AUTOSAR XML (schema 00046)
package /ComponentTypes
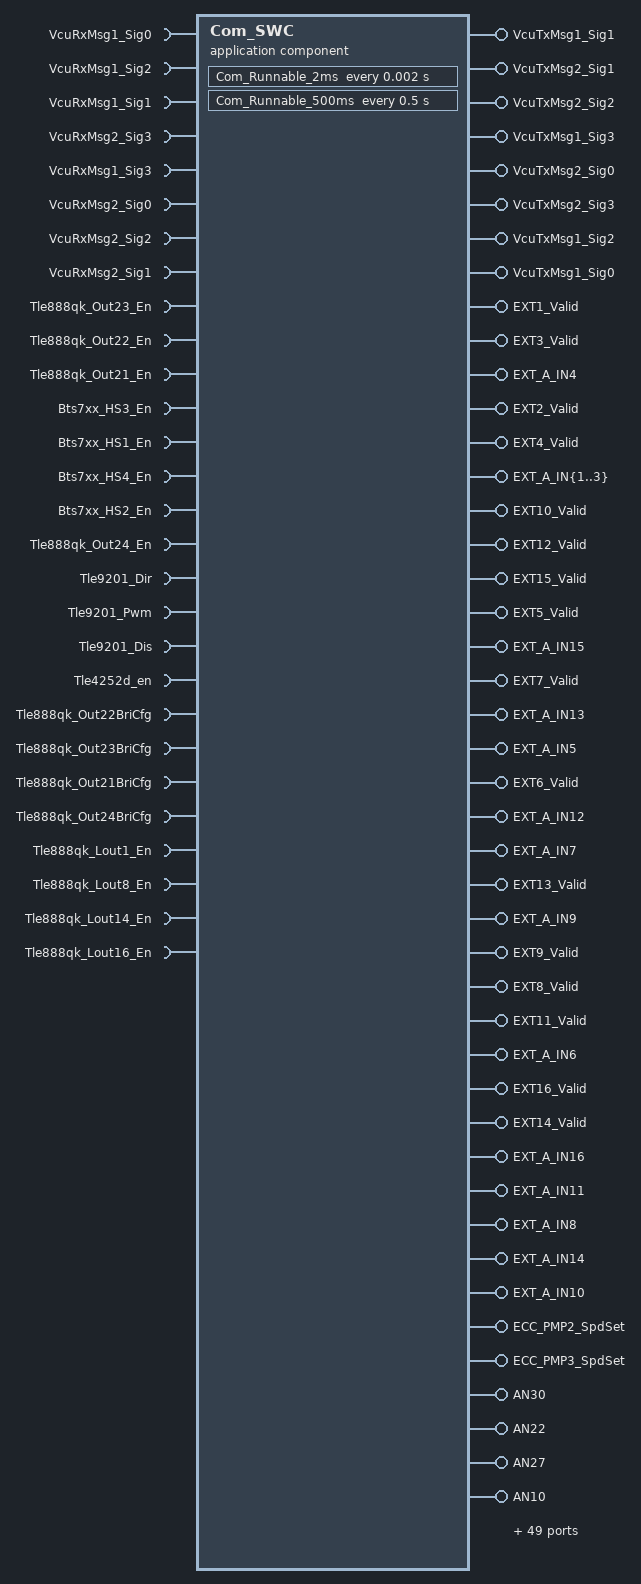
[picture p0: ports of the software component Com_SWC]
  application sw component type Com_SWC
    8 x require port:
      VcuRxMsg1_Sig0: nonqueued-receiver-com-spec{data-element=VcuRxMsg1_Sig0, alive-timeout=2, init-value=0}, required-interface=VcuRxMsg1_Sig0
      VcuRxMsg1_Sig2: nonqueued-receiver-com-spec{data-element=VcuRxMsg1_Sig2, alive-timeout=2, init-value=0}, required-interface=VcuRxMsg1_Sig2
      VcuRxMsg1_Sig1: nonqueued-receiver-com-spec{data-element=VcuRxMsg1_Sig1, alive-timeout=2, init-value=0}, required-interface=VcuRxMsg1_Sig1
      VcuRxMsg2_Sig3: nonqueued-receiver-com-spec{data-element=VcuRxMsg2_Sig3, alive-timeout=2, init-value=0}, required-interface=VcuRxMsg2_Sig3
      VcuRxMsg1_Sig3: nonqueued-receiver-com-spec{data-element=VcuRxMsg1_Sig3, alive-timeout=2, init-value=0}, required-interface=VcuRxMsg1_Sig3
      VcuRxMsg2_Sig0: nonqueued-receiver-com-spec{data-element=VcuRxMsg2_Sig0, alive-timeout=2, init-value=0}, required-interface=VcuRxMsg2_Sig0
      VcuRxMsg2_Sig2: nonqueued-receiver-com-spec{data-element=VcuRxMsg2_Sig2, alive-timeout=2, init-value=0}, required-interface=VcuRxMsg2_Sig2
      VcuRxMsg2_Sig1: nonqueued-receiver-com-spec{data-element=VcuRxMsg2_Sig1, alive-timeout=2, init-value=0}, required-interface=VcuRxMsg2_Sig1
    90 x provide port:
      VcuTxMsg1_Sig1: nonqueued-sender-com-spec{data-element=VcuTxMsg1_Sig1, init-value=0}, provided-interface=VcuTxMsg1_Sig1
      VcuTxMsg2_Sig1: nonqueued-sender-com-spec{data-element=VcuTxMsg2_Sig1, init-value=0}, provided-interface=VcuTxMsg2_Sig1
      VcuTxMsg2_Sig2: nonqueued-sender-com-spec{data-element=VcuTxMsg2_Sig2, init-value=0}, provided-interface=VcuTxMsg2_Sig2
      VcuTxMsg1_Sig3: nonqueued-sender-com-spec{data-element=VcuTxMsg1_Sig3, init-value=0}, provided-interface=VcuTxMsg1_Sig3
      VcuTxMsg2_Sig0: nonqueued-sender-com-spec{data-element=VcuTxMsg2_Sig0, init-value=0}, provided-interface=VcuTxMsg2_Sig0
      VcuTxMsg2_Sig3: nonqueued-sender-com-spec{data-element=VcuTxMsg2_Sig3, init-value=0}, provided-interface=VcuTxMsg2_Sig3
      VcuTxMsg1_Sig2: nonqueued-sender-com-spec{data-element=VcuTxMsg1_Sig2, init-value=0}, provided-interface=VcuTxMsg1_Sig2
      VcuTxMsg1_Sig0: nonqueued-sender-com-spec{data-element=VcuTxMsg1_Sig0, init-value=0}, provided-interface=VcuTxMsg1_Sig0
      EXT1_Valid: nonqueued-sender-com-spec{data-element=EXT1_Valid, init-value=0}, provided-interface=EXT1_Valid
      EXT3_Valid: nonqueued-sender-com-spec{data-element=EXT3_Valid, init-value=0}, provided-interface=EXT3_Valid
      EXT_A_IN4: nonqueued-sender-com-spec{data-element=EXT_A_IN4, init-value=0}, provided-interface=EXT_A_IN4
      EXT2_Valid: nonqueued-sender-com-spec{data-element=EXT2_Valid, init-value=0}, provided-interface=EXT2_Valid
      EXT4_Valid: nonqueued-sender-com-spec{data-element=EXT4_Valid, init-value=0}, provided-interface=EXT4_Valid
      EXT_A_IN{1..3}: nonqueued-sender-com-spec{data-element=EXT_A_IN{1..3}, init-value=0}, provided-interface=EXT_A_IN{1..3}
      EXT10_Valid: nonqueued-sender-com-spec{data-element=EXT10_Valid, init-value=0}, provided-interface=EXT10_Valid
      EXT12_Valid: nonqueued-sender-com-spec{data-element=EXT12_Valid, init-value=0}, provided-interface=EXT12_Valid
      EXT15_Valid: nonqueued-sender-com-spec{data-element=EXT15_Valid, init-value=0}, provided-interface=EXT15_Valid
      EXT5_Valid: nonqueued-sender-com-spec{data-element=EXT5_Valid, init-value=0}, provided-interface=EXT5_Valid
      EXT_A_IN15: nonqueued-sender-com-spec{data-element=EXT_A_IN15, init-value=0}, provided-interface=EXT_A_IN15
      EXT7_Valid: nonqueued-sender-com-spec{data-element=EXT7_Valid, init-value=0}, provided-interface=EXT7_Valid
      EXT_A_IN13: nonqueued-sender-com-spec{data-element=EXT_A_IN13, init-value=0}, provided-interface=EXT_A_IN13
      EXT_A_IN5: nonqueued-sender-com-spec{data-element=EXT_A_IN5, init-value=0}, provided-interface=EXT_A_IN5
      EXT6_Valid: nonqueued-sender-com-spec{data-element=EXT6_Valid, init-value=0}, provided-interface=EXT6_Valid
      EXT_A_IN12: nonqueued-sender-com-spec{data-element=EXT_A_IN12, init-value=0}, provided-interface=EXT_A_IN12
      EXT_A_IN7: nonqueued-sender-com-spec{data-element=EXT_A_IN7, init-value=0}, provided-interface=EXT_A_IN7
      EXT13_Valid: nonqueued-sender-com-spec{data-element=EXT13_Valid, init-value=0}, provided-interface=EXT13_Valid
      EXT_A_IN9: nonqueued-sender-com-spec{data-element=EXT_A_IN9, init-value=0}, provided-interface=EXT_A_IN9
      EXT9_Valid: nonqueued-sender-com-spec{data-element=EXT9_Valid, init-value=0}, provided-interface=EXT9_Valid
      EXT8_Valid: nonqueued-sender-com-spec{data-element=EXT8_Valid, init-value=0}, provided-interface=EXT8_Valid
      EXT11_Valid: nonqueued-sender-com-spec{data-element=EXT11_Valid, init-value=0}, provided-interface=EXT11_Valid
      EXT_A_IN6: nonqueued-sender-com-spec{data-element=EXT_A_IN6, init-value=0}, provided-interface=EXT_A_IN6
      EXT16_Valid: nonqueued-sender-com-spec{data-element=EXT16_Valid, init-value=0}, provided-interface=EXT16_Valid
      EXT14_Valid: nonqueued-sender-com-spec{data-element=EXT14_Valid, init-value=0}, provided-interface=EXT14_Valid
      EXT_A_IN16: nonqueued-sender-com-spec{data-element=EXT_A_IN16, init-value=0}, provided-interface=EXT_A_IN16
      EXT_A_IN11: nonqueued-sender-com-spec{data-element=EXT_A_IN11, init-value=0}, provided-interface=EXT_A_IN11
      EXT_A_IN8: nonqueued-sender-com-spec{data-element=EXT_A_IN8, init-value=0}, provided-interface=EXT_A_IN8
      EXT_A_IN14: nonqueued-sender-com-spec{data-element=EXT_A_IN14, init-value=0}, provided-interface=EXT_A_IN14
      EXT_A_IN10: nonqueued-sender-com-spec{data-element=EXT_A_IN10, init-value=0}, provided-interface=EXT_A_IN10
      ECC_PMP2_SpdSet: nonqueued-sender-com-spec{data-element=ECC_PMP2_SpdSet, init-value=0}, provided-interface=ECC_PMP2_SpdSet
      ECC_PMP3_SpdSet: nonqueued-sender-com-spec{data-element=ECC_PMP3_SpdSet, init-value=0}, provided-interface=ECC_PMP3_SpdSet
      AN30: nonqueued-sender-com-spec{data-element=AN30, init-value=0}, provided-interface=AN30
      AN22: nonqueued-sender-com-spec{data-element=AN22, init-value=0}, provided-interface=AN22
      AN27: nonqueued-sender-com-spec{data-element=AN27, init-value=0}, provided-interface=AN27
      AN10: nonqueued-sender-com-spec{data-element=AN10, init-value=0}, provided-interface=AN10
      AN24: nonqueued-sender-com-spec{data-element=AN24, init-value=0}, provided-interface=AN24
      AN13: nonqueued-sender-com-spec{data-element=AN13, init-value=0}, provided-interface=AN13
      AN8: nonqueued-sender-com-spec{data-element=AN8, init-value=0}, provided-interface=AN8
      AN0: nonqueued-sender-com-spec{data-element=AN0, init-value=0}, provided-interface=AN0
      AN26: nonqueued-sender-com-spec{data-element=AN26, init-value=0}, provided-interface=AN26
      AN29: nonqueued-sender-com-spec{data-element=AN29, init-value=0}, provided-interface=AN29
      AN3: nonqueued-sender-com-spec{data-element=AN3, init-value=0}, provided-interface=AN3
      AN19: nonqueued-sender-com-spec{data-element=AN19, init-value=0}, provided-interface=AN19
      AN14: nonqueued-sender-com-spec{data-element=AN14, init-value=0}, provided-interface=AN14
      AN42: nonqueued-sender-com-spec{data-element=AN42, init-value=0}, provided-interface=AN42
      AN25: nonqueued-sender-com-spec{data-element=AN25, init-value=0}, provided-interface=AN25
      AN12: nonqueued-sender-com-spec{data-element=AN12, init-value=0}, provided-interface=AN12
      AN9: nonqueued-sender-com-spec{data-element=AN9, init-value=0}, provided-interface=AN9
      AN31: nonqueued-sender-com-spec{data-element=AN31, init-value=0}, provided-interface=AN31
      AN18: nonqueued-sender-com-spec{data-element=AN18, init-value=0}, provided-interface=AN18
      AN5: nonqueued-sender-com-spec{data-element=AN5, init-value=0}, provided-interface=AN5
      AN20: nonqueued-sender-com-spec{data-element=AN20, init-value=0}, provided-interface=AN20
      AN43: nonqueued-sender-com-spec{data-element=AN43, init-value=0}, provided-interface=AN43
      AN15: nonqueued-sender-com-spec{data-element=AN15, init-value=0}, provided-interface=AN15
      AN46: nonqueued-sender-com-spec{data-element=AN46, init-value=0}, provided-interface=AN46
      AN32: nonqueued-sender-com-spec{data-element=AN32, init-value=0}, provided-interface=AN32
      AN34: nonqueued-sender-com-spec{data-element=AN34, init-value=0}, provided-interface=AN34
      AN36: nonqueued-sender-com-spec{data-element=AN36, init-value=0}, provided-interface=AN36
      AN41: nonqueued-sender-com-spec{data-element=AN41, init-value=0}, provided-interface=AN41
      AN44: nonqueued-sender-com-spec{data-element=AN44, init-value=0}, provided-interface=AN44
      AN6: nonqueued-sender-com-spec{data-element=AN6, init-value=0}, provided-interface=AN6
      AN2: nonqueued-sender-com-spec{data-element=AN2, init-value=0}, provided-interface=AN2
      AN7: nonqueued-sender-com-spec{data-element=AN7, init-value=0}, provided-interface=AN7
      AN11: nonqueued-sender-com-spec{data-element=AN11, init-value=0}, provided-interface=AN11
      AN40: nonqueued-sender-com-spec{data-element=AN40, init-value=0}, provided-interface=AN40
      AN47: nonqueued-sender-com-spec{data-element=AN47, init-value=0}, provided-interface=AN47
      AN1: nonqueued-sender-com-spec{data-element=AN1, init-value=0}, provided-interface=AN1
      AN28: nonqueued-sender-com-spec{data-element=AN28, init-value=0}, provided-interface=AN28
      AN37: nonqueued-sender-com-spec{data-element=AN37, init-value=0}, provided-interface=AN37
      AN21: nonqueued-sender-com-spec{data-element=AN21, init-value=0}, provided-interface=AN21
      AN33: nonqueued-sender-com-spec{data-element=AN33, init-value=0}, provided-interface=AN33
      AN23: nonqueued-sender-com-spec{data-element=AN23, init-value=0}, provided-interface=AN23
      AN4: nonqueued-sender-com-spec{data-element=AN4, init-value=0}, provided-interface=AN4
      AN16: nonqueued-sender-com-spec{data-element=AN16, init-value=0}, provided-interface=AN16
      AN17: nonqueued-sender-com-spec{data-element=AN17, init-value=0}, provided-interface=AN17
      AN35: nonqueued-sender-com-spec{data-element=AN35, init-value=0}, provided-interface=AN35
      AN45: nonqueued-sender-com-spec{data-element=AN45, init-value=0}, provided-interface=AN45
      AN38: nonqueued-sender-com-spec{data-element=AN38, init-value=0}, provided-interface=AN38
      AN39: nonqueued-sender-com-spec{data-element=AN39, init-value=0}, provided-interface=AN39
    16 x require port:
      Tle888qk_Out23_En: nonqueued-receiver-com-spec{data-element=Tle888qk_Out23_En, init-value=0}, required-interface=Tle888qk_Out23_En
      Tle888qk_Out22_En: nonqueued-receiver-com-spec{data-element=Tle888qk_Out22_En, init-value=0}, required-interface=Tle888qk_Out22_En
      Tle888qk_Out21_En: nonqueued-receiver-com-spec{data-element=Tle888qk_Out21_En, init-value=0}, required-interface=Tle888qk_Out21_En
      Bts7xx_HS3_En: nonqueued-receiver-com-spec{data-element=Bts7xx_HS3_En, init-value=0}, required-interface=Bts7xx_HS3_En
      Bts7xx_HS1_En: nonqueued-receiver-com-spec{data-element=Bts7xx_HS1_En, init-value=0}, required-interface=Bts7xx_HS1_En
      Bts7xx_HS4_En: nonqueued-receiver-com-spec{data-element=Bts7xx_HS4_En, init-value=0}, required-interface=Bts7xx_HS4_En
      Bts7xx_HS2_En: nonqueued-receiver-com-spec{data-element=Bts7xx_HS2_En, init-value=0}, required-interface=Bts7xx_HS2_En
      Tle888qk_Out24_En: nonqueued-receiver-com-spec{data-element=Tle888qk_Out24_En, init-value=0}, required-interface=Tle888qk_Out24_En
      Tle9201_Dir: nonqueued-receiver-com-spec{data-element=Tle9201_Dir, init-value=0}, required-interface=Tle9201_Dir
      Tle9201_Pwm: nonqueued-receiver-com-spec{data-element=Tle9201_Pwm, init-value=0}, required-interface=Tle9201_Pwm
      Tle9201_Dis: nonqueued-receiver-com-spec{data-element=Tle9201_Dis, init-value=0}, required-interface=Tle9201_Dis
      Tle4252d_en: nonqueued-receiver-com-spec{data-element=Tle4252d_en, init-value=0}, required-interface=Tle4252d_en
      Tle888qk_Out22BriCfg: nonqueued-receiver-com-spec{data-element=Tle888qk_Out22BriCfg, init-value=0}, required-interface=Tle888qk_Out22BriCfg
      Tle888qk_Out23BriCfg: nonqueued-receiver-com-spec{data-element=Tle888qk_Out23BriCfg, init-value=0}, required-interface=Tle888qk_Out23BriCfg
      Tle888qk_Out21BriCfg: nonqueued-receiver-com-spec{data-element=Tle888qk_Out21BriCfg, init-value=0}, required-interface=Tle888qk_Out21BriCfg
      Tle888qk_Out24BriCfg: nonqueued-receiver-com-spec{data-element=Tle888qk_Out24BriCfg, init-value=0}, required-interface=Tle888qk_Out24BriCfg
    5 x provide port:
      Ext_IN2: nonqueued-sender-com-spec{data-element=Ext_IN2, init-value=0}, provided-interface=Ext_IN2
      EXT_PWM_IN1_Duty: nonqueued-sender-com-spec{data-element=EXT_PWM_IN1_Duty, init-value=0}, provided-interface=EXT_PWM_IN1_Duty
      EXT_PWM_IN2_Duty: nonqueued-sender-com-spec{data-element=EXT_PWM_IN2_Duty, init-value=0}, provided-interface=EXT_PWM_IN2_Duty
      EXT_PWM_IN2_Period: nonqueued-sender-com-spec{data-element=EXT_PWM_IN2_Period, init-value=0}, provided-interface=EXT_PWM_IN2_Period
      EXT_PWM_IN1_Period: nonqueued-sender-com-spec{data-element=EXT_PWM_IN1_Period, init-value=0}, provided-interface=EXT_PWM_IN1_Period
    4 x require port:
      Tle888qk_Lout1_En: nonqueued-receiver-com-spec{data-element=Tle888qk_Lout1_En, init-value=0}, required-interface=Tle888qk_Lout1_En
      Tle888qk_Lout8_En: nonqueued-receiver-com-spec{data-element=Tle888qk_Lout8_En, init-value=0}, required-interface=Tle888qk_Lout8_En
      Tle888qk_Lout14_En: nonqueued-receiver-com-spec{data-element=Tle888qk_Lout14_En, init-value=0}, required-interface=Tle888qk_Lout14_En
      Tle888qk_Lout16_En: nonqueued-receiver-com-spec{data-element=Tle888qk_Lout16_En, init-value=0}, required-interface=Tle888qk_Lout16_En
    behavior Com_SWC_InternalBehavior
      data received event DRT_Rte_Msg200h_Rx_Notification_VcuRxMsg1_Sig0_VcuRxMsg1_Sig0: start-on-event=Rte_Msg200h_Rx_Notification, data=VcuRxMsg1_Sig0.VcuRxMsg1_Sig0
      data received event DRT_Rte_Msg201h_Rx_Notification_VcuRxMsg2_Sig0_VcuRxMsg2_Sig0: start-on-event=Rte_Msg201h_Rx_Notification, data=VcuRxMsg2_Sig0.VcuRxMsg2_Sig0
      timing event TMT_Com_Runnable_2ms: start-on-event=Com_Runnable_2ms, period=0.002
      timing event TMT_Com_Runnable_20ms: start-on-event=Com_Runnable_500ms, period=0.5
      data received event DRT_Rte_Msg10Eh_Rx_Notification_Tle888qk_Out21_En_Tle888qk_Out21_En: start-on-event=Rte_Msg10Eh_Rx_Notification, data=Tle888qk_Out21_En.Tle888qk_Out21_En
      data received event DRT_Rte_Msg10Fh_Rx_Notification_Bts7xx_HS1_En_Bts7xx_HS1_En: start-on-event=Rte_Msg10Fh_Rx_Notification, data=Bts7xx_HS1_En.Bts7xx_HS1_En
      data received event DRT_Rte_Msg110h_Rx_Notification_Tle888qk_Lout1_En_Tle888qk_Lout1_En: start-on-event=Rte_Msg110h_Rx_Notification, data=Tle888qk_Lout1_En.Tle888qk_Lout1_En
      7 x runnable:
        Rte_Msg200h_Rx_Notification
        Rte_Msg201h_Rx_Notification
        Com_Runnable_2ms
          data-receive-point-by-arguments:
            28 x access:
              REC_VcuRxMsg1_Sig{0..3}_VcuRxMsg1_Sig{0..3}: accessed-variable=VcuRxMsg1_Sig{0..3}.VcuRxMsg1_Sig{0..3}
              REC_VcuRxMsg2_Sig{0..3}_VcuRxMsg2_Sig{0..3}: accessed-variable=VcuRxMsg2_Sig{0..3}.VcuRxMsg2_Sig{0..3}
              REC_Bts7xx_HS{1..4}_En_Bts7xx_HS{1..4}_En: accessed-variable=Bts7xx_HS{1..4}_En.Bts7xx_HS{1..4}_En
              REC_Tle888qk_Out{21..24}_En_Tle888qk_Out{21..24}_En: accessed-variable=Tle888qk_Out{21..24}_En.Tle888qk_Out{21..24}_En
              REC_Tle4252d_en_Tle4252d_en: accessed-variable=Tle4252d_en.Tle4252d_en
              REC_Tle888qk_Out{21..24}BriCfg_Tle888qk_Out{21..24}BriCfg: accessed-variable=Tle888qk_Out{21..24}BriCfg.Tle888qk_Out{21..24}BriCfg
              REC_Tle9201_Dir_Tle9201_Dir: accessed-variable=Tle9201_Dir.Tle9201_Dir
              REC_Tle9201_Dis_Tle9201_Dis: accessed-variable=Tle9201_Dis.Tle9201_Dis
              REC_Tle9201_Pwm_Tle9201_Pwm: accessed-variable=Tle9201_Pwm.Tle9201_Pwm
              REC_Tle888qk_Lout14_En_Tle888qk_Lout14_En: accessed-variable=Tle888qk_Lout14_En.Tle888qk_Lout14_En
              REC_Tle888qk_Lout16_En_Tle888qk_Lout16_En: accessed-variable=Tle888qk_Lout16_En.Tle888qk_Lout16_En
              REC_Tle888qk_Lout1_En_Tle888qk_Lout1_En: accessed-variable=Tle888qk_Lout1_En.Tle888qk_Lout1_En
              REC_Tle888qk_Lout8_En_Tle888qk_Lout8_En: accessed-variable=Tle888qk_Lout8_En.Tle888qk_Lout8_En
          data-send-points:
            47 x access:
              SEND_VcuTxMsg1_Sig{0..3}_VcuTxMsg1_Sig{0..3}: accessed-variable=VcuTxMsg1_Sig{0..3}.VcuTxMsg1_Sig{0..3}
              SEND_VcuTxMsg2_Sig{0..3}_VcuTxMsg2_Sig{0..3}: accessed-variable=VcuTxMsg2_Sig{0..3}.VcuTxMsg2_Sig{0..3}
              SEND_EXT{1..4}_Valid_EXT{1..4}_Valid: accessed-variable=EXT{1..4}_Valid.EXT{1..4}_Valid
              SEND_EXT_A_IN{1..4}_EXT_A_IN{1..4}: accessed-variable=EXT_A_IN{1..4}.EXT_A_IN{1..4}
              SEND_EXT{10..16}_Valid_EXT{10..16}_Valid: accessed-variable=EXT{10..16}_Valid.EXT{10..16}_Valid
              SEND_EXT{5..9}_Valid_EXT{5..9}_Valid: accessed-variable=EXT{5..9}_Valid.EXT{5..9}_Valid
              SEND_EXT_A_IN{10..16}_EXT_A_IN{10..16}: accessed-variable=EXT_A_IN{10..16}.EXT_A_IN{10..16}
              SEND_EXT_A_IN{5..9}_EXT_A_IN{5..9}: accessed-variable=EXT_A_IN{5..9}.EXT_A_IN{5..9}
              SEND_ECC_PMP2_SpdSet_ECC_PMP2_SpdSet: accessed-variable=ECC_PMP2_SpdSet.ECC_PMP2_SpdSet
              SEND_ECC_PMP3_SpdSet_ECC_PMP3_SpdSet: accessed-variable=ECC_PMP3_SpdSet.ECC_PMP3_SpdSet
              SEND_EXT_PWM_IN1_Duty_EXT_PWM_IN1_Duty: accessed-variable=EXT_PWM_IN1_Duty.EXT_PWM_IN1_Duty
              SEND_EXT_PWM_IN1_Period_EXT_PWM_IN1_Period: accessed-variable=EXT_PWM_IN1_Period.EXT_PWM_IN1_Period
              SEND_EXT_PWM_IN2_Duty_EXT_PWM_IN2_Duty: accessed-variable=EXT_PWM_IN2_Duty.EXT_PWM_IN2_Duty
              SEND_EXT_PWM_IN2_Period_EXT_PWM_IN2_Period: accessed-variable=EXT_PWM_IN2_Period.EXT_PWM_IN2_Period
              SEND_Ext_IN2_Ext_IN2: accessed-variable=Ext_IN2.Ext_IN2
        Com_Runnable_500ms
          data-send-points:
            48 x access:
              SEND_AN0_AN0: accessed-variable=AN0.AN0
              SEND_AN1_AN1: accessed-variable=AN1.AN1
              SEND_AN{10..19}_AN{10..19}: accessed-variable=AN{10..19}.AN{10..19}
              SEND_AN2_AN2: accessed-variable=AN2.AN2
              SEND_AN{20..29}_AN{20..29}: accessed-variable=AN{20..29}.AN{20..29}
              SEND_AN3_AN3: accessed-variable=AN3.AN3
              SEND_AN{30..39}_AN{30..39}: accessed-variable=AN{30..39}.AN{30..39}
              SEND_AN4_AN4: accessed-variable=AN4.AN4
              SEND_AN{40..47}_AN{40..47}: accessed-variable=AN{40..47}.AN{40..47}
              SEND_AN{5..9}_AN{5..9}: accessed-variable=AN{5..9}.AN{5..9}
        Rte_Msg10Eh_Rx_Notification
        Rte_Msg10Fh_Rx_Notification
        Rte_Msg110h_Rx_Notification
  swc implementation Com_SWC_Implementation: behavior=Com_SWC_InternalBehavior
